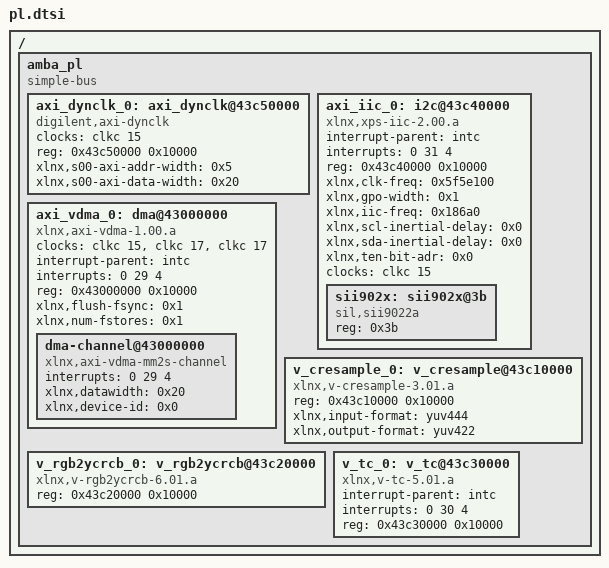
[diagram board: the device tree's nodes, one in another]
/*
 * CAUTION: This file is automatically generated by Xilinx.
 * Version: HSI 2015.4
 * Today is: Sat Sep  9 16:34:59 2017
*/


/ {
	amba_pl: amba_pl {
		#address-cells = <1>;
		#size-cells = <1>;
		compatible = "simple-bus";
		ranges ;
		axi_dynclk_0: axi_dynclk@43c50000 {
			compatible = "digilent,axi-dynclk";
			#clock-cells = <0>;
			clocks = <&clkc 15>;
			reg = <0x43c50000 0x10000>;
			xlnx,s00-axi-addr-width = <0x5>;
			xlnx,s00-axi-data-width = <0x20>;
		};
		axi_iic_0: i2c@43c40000 {
			#address-cells = <1>;
			#size-cells = <0>;
			compatible = "xlnx,xps-iic-2.00.a";
			interrupt-parent = <&intc>;
			interrupts = <0 31 4>;
			reg = <0x43c40000 0x10000>;
			xlnx,clk-freq = <0x5f5e100>;
			xlnx,gpo-width = <0x1>;
			xlnx,iic-freq = <0x186a0>;
			xlnx,scl-inertial-delay = <0x0>;
			xlnx,sda-inertial-delay = <0x0>;
			xlnx,ten-bit-adr = <0x0>;
			clocks = <&clkc 15>;

			sii902x: sii902x@3b {
				compatible = "sil,sii9022a";
				reg = <0x3b>;
			};
		};
		axi_vdma_0: dma@43000000 {
			#dma-cells = <1>;
			clock-names = "s_axi_lite_aclk", "m_axi_mm2s_aclk", "m_axis_mm2s_aclk";
                        clocks = <&clkc 15>, <&clkc 17>, <&clkc 17>;
			compatible = "xlnx,axi-vdma-1.00.a";
			interrupt-parent = <&intc>;
			interrupts = <0 29 4>;
			reg = <0x43000000 0x10000>;
			xlnx,flush-fsync = <0x1>;
			xlnx,num-fstores = <0x1>;
			dma-channel@43000000 {
				compatible = "xlnx,axi-vdma-mm2s-channel";
				interrupts = <0 29 4>;
				xlnx,datawidth = <0x20>;
				xlnx,device-id = <0x0>;
			};
		};
		v_cresample_0: v_cresample@43c10000 {
			compatible = "xlnx,v-cresample-3.01.a";
			reg = <0x43c10000 0x10000>;
			xlnx,input-format = "yuv444";
			xlnx,output-format = "yuv422";
		};
		v_rgb2ycrcb_0: v_rgb2ycrcb@43c20000 {
			compatible = "xlnx,v-rgb2ycrcb-6.01.a";
			reg = <0x43c20000 0x10000>;
		};
		v_tc_0: v_tc@43c30000 {
			compatible = "xlnx,v-tc-5.01.a";
			interrupt-parent = <&intc>;
			interrupts = <0 30 4>;
			reg = <0x43c30000 0x10000>;
		};
	};
};
